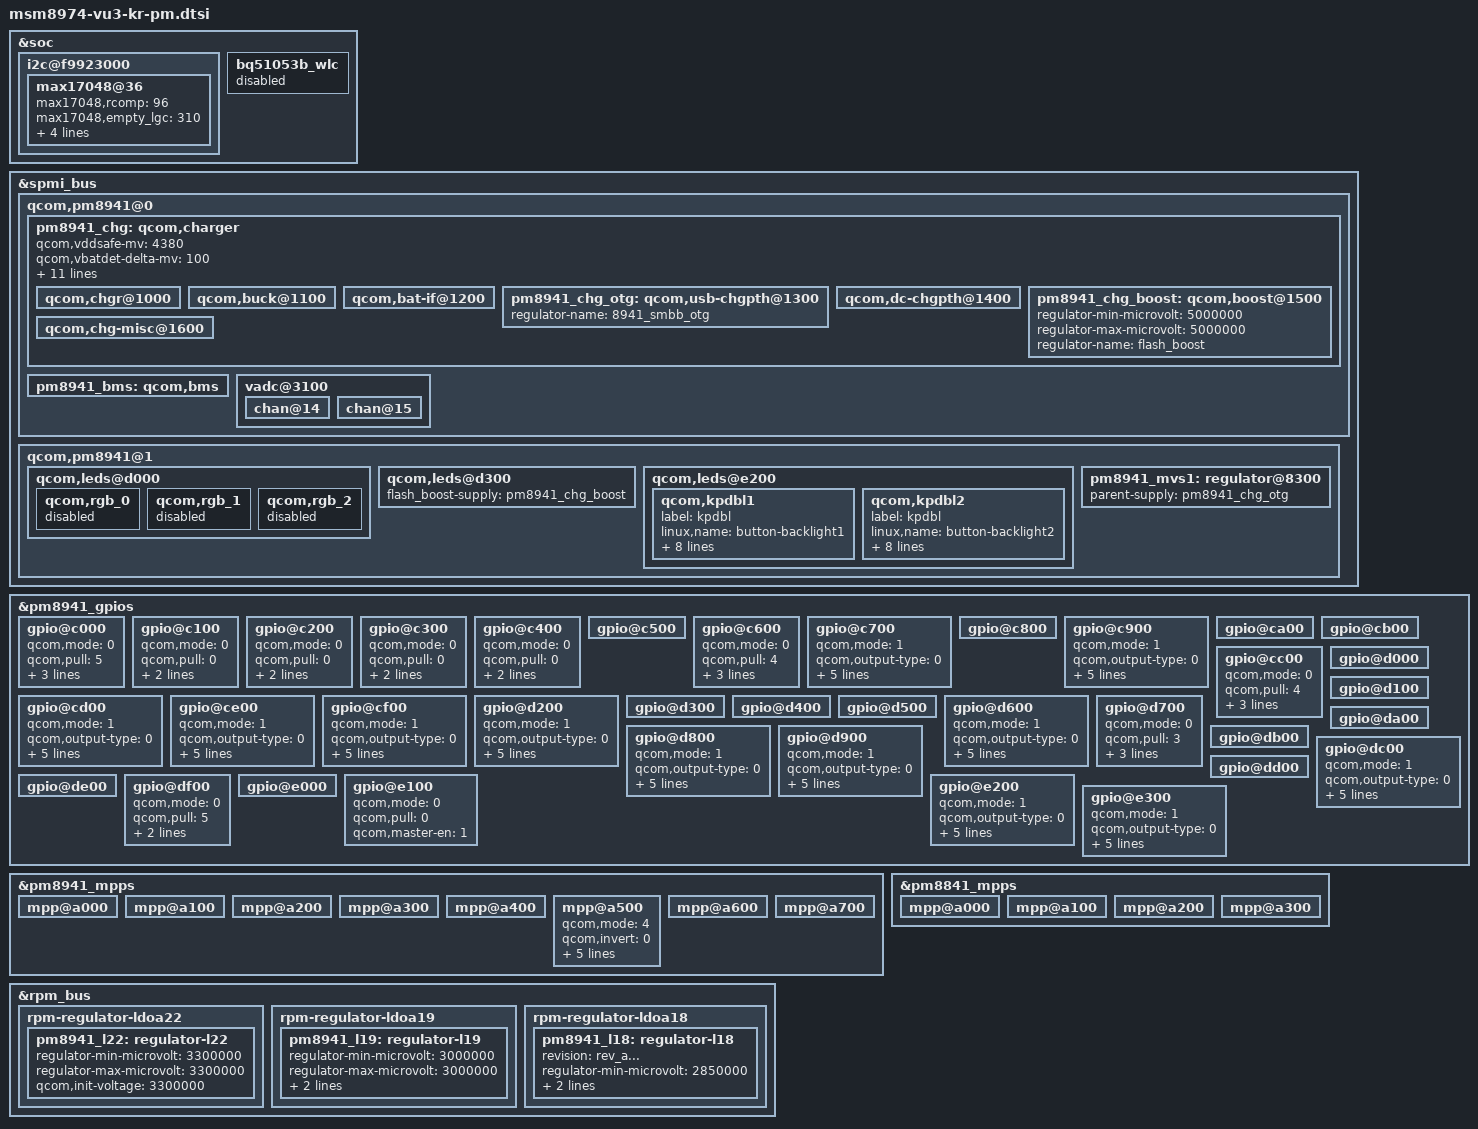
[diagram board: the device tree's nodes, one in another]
/* Copyright (c) 2012, Code Aurora Forum. All rights reserved.
 *
 * This program is free software; you can redistribute it and/or modify
* it under the terms of the GNU General Public License version 2 and
* only version 2 as published by the Free Software Foundation.
*
* This program is distributed in the hope that it will be useful,
* but WITHOUT ANY WARRANTY; without even the implied warranty of
* MERCHANTABILITY or FITNESS FOR A PARTICULAR PURPOSE.  See the
* GNU General Public License for more details.
*/

&soc {
	i2c@f9923000 {
		max17048@36 {
			status =  "ok";
			max17048,rcomp = <96>;
			max17048,empty_lgc = <310>;     /* 3.3 Cut-off 3.1%  */
			max17048,empty_tocad = <484>;   /* 3.3 Cut-off 4.84% */
			max17048,temp_co_hot = <25>;
			max17048,temp_co_cold = <7400>;
			max17048,full_design = <2540>;
		};

	};

	bq51053b_wlc {
		status = "disabled";
	};
};

&spmi_bus {
	qcom,pm8941@0 {

		pm8941_chg: qcom,charger {
			status = "ok";
			qcom,vddsafe-mv = <4380>;
			qcom,vbatdet-delta-mv = <100>;
			qcom,ibatterm-ma = <100>;
			qcom,tchg-mins = <480>;
			qcom,maxinput-dc-ma = <700>;
			qcom,bpd-detection = "bpd_thm";
			qcom,cool-bat-decidegc = <0>;
			qcom,warm-bat-decidegc = <0>;

			lge,cable-130k = <340000 500 500>;
			lge,cable-none = <1900000 1300  500>;
			wlc_track = <&msmgpio 24 0>;
			wlc_full_chg = <&pm8941_gpios 36 0>;
			otg-parent-supply = <&pm8941_boost>;

			qcom,chgr@1000 {
				status = "ok";
			};

			qcom,buck@1100 {
				status = "ok";
			};

			qcom,bat-if@1200 {
				status = "ok";
			};

			pm8941_chg_otg: qcom,usb-chgpth@1300 {
				status = "ok";
				regulator-name = "8941_smbb_otg";
			};

			qcom,dc-chgpth@1400 {
				status = "ok";
			};

			pm8941_chg_boost: qcom,boost@1500 {
				status = "ok";
				regulator-min-microvolt = <5000000>;
				regulator-max-microvolt = <5000000>;
				regulator-name = "flash_boost";
			};

			qcom,chg-misc@1600 {
				status = "ok";
			};
		};

		pm8941_bms: qcom,bms  {
             status = "ok";
	    };
		vadc@3100 {
			chan@14 {
				status = "ok";
			};
			chan@15 {
				status = "ok";
			};
		};

	};

	qcom,pm8941@1 {
	    qcom,leds@d000 {
	            qcom,rgb_0 {
	                    status = "disable";
	            };

	            qcom,rgb_1 {
	                    status = "disable";
	            };

	            qcom,rgb_2 {
	                    status = "disable";
	            };
	    };

		qcom,leds@d300 {
			flash_boost-supply = <&pm8941_chg_boost>;
		};

		qcom,leds@e200 {
			status = "okay";
			qcom,kpdbl1 {
				label = "kpdbl";
				linux,name = "button-backlight1";
				qcom,mode = "pwm";
				qcom,pwm-channel = <8>;
				qcom,pwm-us = <1000>;
				qcom,id = <7>;
				qcom,max-current = <20>;
				qcom,row-src-sel-val = <0x00>;
				qcom,row-scan-en = <0x01>;
				qcom,row-scan-val = <0x01>;
			};
			qcom,kpdbl2 {
				label = "kpdbl";
				linux,name = "button-backlight2";
				qcom,mode = "pwm";
				qcom,pwm-channel = <9>;
				qcom,pwm-us = <1000>;
				qcom,id = <7>;
				qcom,max-current = <20>;
				qcom,row-src-sel-val = <0x00>;
				qcom,row-scan-en = <0x01>;
				qcom,row-scan-val = <0x01>;
			};
		};
	    pm8941_mvs1: regulator@8300 {
		parent-supply = <&pm8941_chg_otg>;
	    };
	};
};

&pm8941_gpios {
	gpio@c000 { /* GPIO 1 */
		status = "ok";
		qcom,mode = <0>;
		qcom,pull = <5>;
		qcom,vin-sel = <2>;
		qcom,src-select = <0>;
		qcom,master-en = <1>;
	};

	gpio@c100 { /* GPIO 2 */
		qcom,mode = <0>;
		qcom,pull = <0>;
		qcom,vin-sel = <2>;
		qcom,src-sel = <0>;
	};

	gpio@c200 { /* GPIO 3 */
		qcom,mode = <0>;
		qcom,pull = <0>;
		qcom,vin-sel = <2>;
		qcom,src-sel = <0>;
	};

	gpio@c300 { /* GPIO 4 */
		qcom,mode = <0>;
		qcom,pull = <0>;
		qcom,vin-sel = <2>;
		qcom,src-sel = <0>;
	};

	gpio@c400 { /* GPIO 5 */
		qcom,mode = <0>;
		qcom,pull = <0>;
		qcom,vin-sel = <2>;
		qcom,src-sel = <0>;
	};

	gpio@c500 { /* GPIO 6 */
	};

	gpio@c600 { /* GPIO 7 */
		status = "ok";
		qcom,mode = <0>;		/* QPNP_PIN_MODE_DIG_IN */
		qcom,pull = <4>;		/* QPNP_PIN_PULL_DN */
		qcom,vin-sel = <2>;		/* QPNP_PIN_VIN2 */
		qcom,src-select = <0>;		/* QPNP_PIN_SEL_FUNC_CONSTANT */
		qcom,master-en = <1>;
	};

	gpio@c700 { /* GPIO 8 */
		status = "ok";
		qcom,mode = <1>;		/* QPNP_PIN_MODE_DIG_OUT */
		qcom,output-type = <0>;		/* QPNP_PIN_OUT_BUF_CMOS */
		qcom,pull = <5>;		/* QPNP_PIN_PULL_NO */
		qcom,vin-sel = <2>;		/* QPNP_PIN_VIN2 */
		qcom,out-strength = <2>;	/* QPNP_PIN_OUT_STRENGTH_MED */
		qcom,src-select = <0>;		/* QPNP_PIN_SEL_FUNC_CONSTANT */
		qcom,master-en = <1>;
	};

	gpio@c800 { /* GPIO 9 */
	};

	gpio@c900 { /* GPIO 10 */
		status = "ok";
		qcom,mode = <1>;		/* QPNP_PIN_MODE_DIG_OUT */
		qcom,output-type = <0>;		/* QPNP_PIN_OUT_BUF_CMOS */
		qcom,pull = <5>;		/* QPNP_PIN_PULL_NO */
		qcom,vin-sel = <2>;		/* QPNP_PIN_VIN2 */
		qcom,out-strength = <2>;	/* QPNP_PIN_OUT_STRENGTH_MED */
		qcom,src-select = <0>;		/* QPNP_PIN_SEL_FUNC_CONSTANT */
		qcom,master-en = <1>;
	};

	gpio@ca00 { /* GPIO 11 */
	};

	gpio@cb00 { /* GPIO 12 */
	};

	gpio@cc00 { /* GPIO 13 */ /* LGE_CHANGE, SlimPort Cable Det IRQ */
		status = "ok";
		qcom,mode = <0>;		/* QPNP_PIN_MODE_DIG_IN */
		qcom,pull = <4>;		/* QPNP_PIN_PULL_DN */
		qcom,vin-sel = <2>;		/* QPNP_PIN_VIN2 */
		qcom,src-sel = <0>;		/* QPNP_PIN_SEL_FUNC_CONSTANT */
		qcom,master-en = <1>;
	};

	gpio@cd00 { /* GPIO 14 */ /* LGE_CHANGE, SlimPort PWR Ctl Pin Setting */
		status = "ok";
		qcom,mode = <1>;		/* QPNP_PIN_MODE_DIG_OUT */
		qcom,output-type = <0>;		/* QPNP_PIN_OUT_BUF_CMOS */
		qcom,pull = <5>;		/* QPNP_PIN_PULL_NO */
		qcom,vin-sel = <2>;		/* QPNP_PIN_VIN2 */
		qcom,out-strength = <2>;	/* QPNP_PIN_OUT_STRENGTH_MED */
		qcom,src-sel = <0>;		/* QPNP_PIN_SEL_FUNC_CONSTANT */
		qcom,master-en = <1>;
	};

	gpio@ce00 { /* GPIO 15 */
		qcom,mode = <1>;
		qcom,output-type = <0>;
		qcom,pull = <5>;
		qcom,vin-sel = <2>;
		qcom,out-strength = <3>;
		qcom,src-sel = <2>;
		qcom,master-en = <1>;
	};

	gpio@cf00 { /* GPIO 16 */ /* LGE_CHANGE, [BT][younghyun.kwon@lge.com], 2013-02-26, BT Sleep clock(32KHz) configuration since Rev.B*/
		qcom,mode = <1>;
		qcom,output-type = <0>;
		qcom,pull = <5>;
		qcom,vin-sel = <2>;
		qcom,out-strength = <3>;
		qcom,src-sel = <3>;
		qcom,master-en = <1>;
	};

	gpio@d000 { /* GPIO 17 */
	};

	gpio@d100 { /* GPIO 18 */ 
	};

	gpio@d200 { /* GPIO 19 */
		qcom,mode = <1>;		/* QPNP_PIN_MODE_DIG_OUT */
		qcom,output-type = <0>;		/* QPNP_PIN_OUT_BUF_CMOS */
		qcom,pull = <5>;		/* QPNP_PIN_PULL_NO */
		qcom,vin-sel = <2>;		/* QPNP_PIN_VIN2 */
		qcom,out-strength = <2>;	/* QPNP_PIN_OUT_STRENGTH_MED */
		qcom,src-sel = <0>;		/* QPNP_PIN_SEL_FUNC_CONSTANT */
		qcom,master-en = <1>;
	};

	gpio@d300 { /* GPIO 20 */
	};

	gpio@d400 { /* GPIO 21 */
	};

	gpio@d500 { /* GPIO 22 */
	};

	gpio@d600 { /* GPIO 23 */
		status = "ok";			/* wlc_chg_ctrl for boosting of WLC */
		qcom,mode = <1>;		/* QPNP_PIN_MODE_DIG_OUT */
		qcom,output-type = <0>;		/* QPNP_PIN_OUT_BUF_CMOS */
		qcom,pull = <5>;		/* QPNP_PIN_PULL_NO */
		qcom,vin-sel = <0>;		/* QPNP_PIN_VIN0 3.6V */
		qcom,out-strength = <3>;	/* QPNP_PIN_OUT_STRENGTH_HIGH */
		qcom,src-sel = <0>;		/* QPNP_PIN_SEL_FUNC_CONSTANT */
		qcom,master-en = <1>;
	};

	gpio@d700 { /* GPIO 24 */
		status = "ok";			/* active_n_gpio for WLC */
		qcom,mode = <0>;		/* QPNP_PIN_MODE_DIG_IN */
		qcom,pull = <3>;		/* QPNP_PIN_GPIO_PULL_UP_1P5_30 */
		qcom,vin-sel = <2>;		/* QPNP_PIN_VIN2 */
		qcom,src-sel = <0>;		/* QPNP_PIN_SEL_FUNC_CONSTANT */
		qcom,master-en = <1>;
	};

	gpio@d800 { /* GPIO 25 */
		status = "ok";			/* wlc_otg_cntl for WLC */
		qcom,mode = <1>;		/* QPNP_PIN_MODE_DIG_OUT */
		qcom,output-type = <0>;		/* QPNP_PIN_OUT_BUF_CMOS */
		qcom,pull = <5>;		/* QPNP_PIN_PULL_NO */
		qcom,vin-sel = <2>;		/* QPNP_PIN_VIN2 */
		qcom,out-strength = <3>;	/* QPNP_PIN_OUT_STRENGTH_HIGH */
		qcom,src-sel = <0>;		/* QPNP_PIN_SEL_FUNC_CONSTANT */
		qcom,master-en = <1>;
	};

	gpio@d900 { /* GPIO 26 */
		status = "ok";
		qcom,mode = <1>;		/* QPNP_PIN_MODE_DIG_OUT */
		qcom,output-type = <0>;		/* QPNP_PIN_OUT_BUF_CMOS */
		qcom,pull = <5>;		/* QPNP_PIN_PULL_NO */
		qcom,vin-sel = <2>;		/* QPNP_PIN_VIN2 */
		qcom,out-strength = <2>;	/* QPNP_PIN_OUT_STRENGTH_MED */
		qcom,src-select = <0>;		/* QPNP_PIN_SEL_FUNC_CONSTANT */
		qcom,master-en = <1>;
	};

	gpio@da00 { /* GPIO 27 */
	};

	gpio@db00 { /* GPIO 28 */
	};

	gpio@dc00 { /* GPIO 29 */
		status = "ok";
		qcom,mode = <1>;
		qcom,output-type = <0>;
		qcom,pull = <1>; /* set to default pull */
		qcom,out-strength = <2>;
		com,vin-sel = <2>; /* select 1.8 V source */
		qcom,src-select = <0>;      /* QPNP_PIN_SEL_FUNC_CONSTANT */
		qcom,master-en = <1>;
	};

	gpio@dd00 { /* GPIO 30 */
	};

	gpio@de00 { /* GPIO 31 */
	};

	gpio@df00 { /* GPIO 32 */
		status = "ok";
		qcom,mode = <0>;		/* QPNP_PIN_MODE_DIG_IN */
		qcom,pull = <5>;		/* QPNP_PIN_PULL_NO */
		qcom,master-en = <1>;           /* Enable Module */
		qcom,vin-sel = <2>;		/* Select 1.8V Source */
	};

	gpio@e000 { /* GPIO 33 */
	};

	gpio@e100 { /* GPIO 34 */
		status = "ok";			/* wlc_int_gpio for bq51053b */
		qcom,mode = <0>;		/* QPNP_PIN_MODE_DIG_IN */
		qcom,pull = <0>;		/* QPNP_PIN_GPIO_PULL_UP */
		qcom,master-en = <1>;
	};

	gpio@e200 { /* GPIO 35 */
		status = "ok";			/* rgb_led en for lp5521 */
		qcom,mode = <1>;		/* QPNP_PIN_MODE_DIG_OUT */
		qcom,output-type = <0>;		/* QPNP_PIN_OUT_BUF_CMOS */
		qcom,pull = <5>;		/* QPNP_PIN_PULL_NO */
		qcom,vin-sel = <2>;		/* QPNP_PIN_VIN0 1.8V */
		qcom,out-strength = <2>;	/* QPNP_PIN_OUT_STRENGTH_MED */
		qcom,src-sel = <0>;		/* QPNP_PIN_SEL_FUNC_CONSTANT */
		qcom,master-en = <1>;
	};

	gpio@e300 { /* GPIO 36 */
		status = "ok";			/* wlc_full_gpio for bq51053b */
		qcom,mode = <1>;		/* QPNP_PIN_MODE_DIG_OUT */
		qcom,output-type = <0>;		/* QPNP_PIN_OUT_BUF_CMOS */
		qcom,pull = <5>;		/* QPNP_PIN_PULL_NO */
		qcom,vin-sel = <0>;		/* QPNP_PIN_VIN0 3.6V */
		qcom,out-strength = <3>;	/* QPNP_PIN_OUT_STRENGTH_HIGH */
		qcom,src-sel = <0>;		/* QPNP_PIN_SEL_FUNC_CONSTANT */
		qcom,master-en = <1>;
	};
};

&pm8941_mpps {

	mpp@a000 { /* MPP 1 */
	};

	mpp@a100 { /* MPP 2 */
	};

	mpp@a200 { /* MPP 3 */
	};

	mpp@a300 { /* MPP 4 */
	};

	mpp@a400 { /* MPP 5 */
		status = "ok";
	};

	mpp@a500 { /* MPP 6 */
		status = "ok";
		qcom,mode = <4>; /* QPNP_PIN_MODE_AIN */
		qcom,invert = <0>; /*no invert*/
		qcom,output-type = <0>; /* CMOS */
		qcom,vin-sel = <2>; /* PM8941_S3 1.8V > 1.6V */
		qcom,src-sel = <0>; /* CONSTANT */
		qcom,ain-route = <1>;
		qcom,master-en = <1>;
	};

	mpp@a600 { /* MPP 7 */
	};

	mpp@a700 { /* MPP 8 */
	};
};

&pm8841_mpps {

	mpp@a000 { /* MPP 1 */
	};

	mpp@a100 { /* MPP 2 */
	};

	mpp@a200 { /* MPP 3 */
	};

	mpp@a300 { /* MPP 4 */
	};
};

&rpm_bus {
	rpm-regulator-ldoa22 {
		pm8941_l22: regulator-l22 {
			regulator-min-microvolt = <3300000>;
			regulator-max-microvolt = <3300000>;
			qcom,init-voltage = <3300000>;
		};
	};

	rpm-regulator-ldoa19 {
		pm8941_l19: regulator-l19 {
			regulator-min-microvolt = <3000000>;
			regulator-max-microvolt = <3000000>;
			qcom,init-voltage = <3000000>;
			revision = "rev_a...";
		};
	};

	rpm-regulator-ldoa18 {
		status = "okay";
		pm8941_l18: regulator-l18 {
			status = "ok";
			revision = "rev_a...";
			regulator-min-microvolt = <2850000>;
			regulator-max-microvolt = <2850000>;
			qcom,init-voltage = <2850000>;
		};
	};

};
